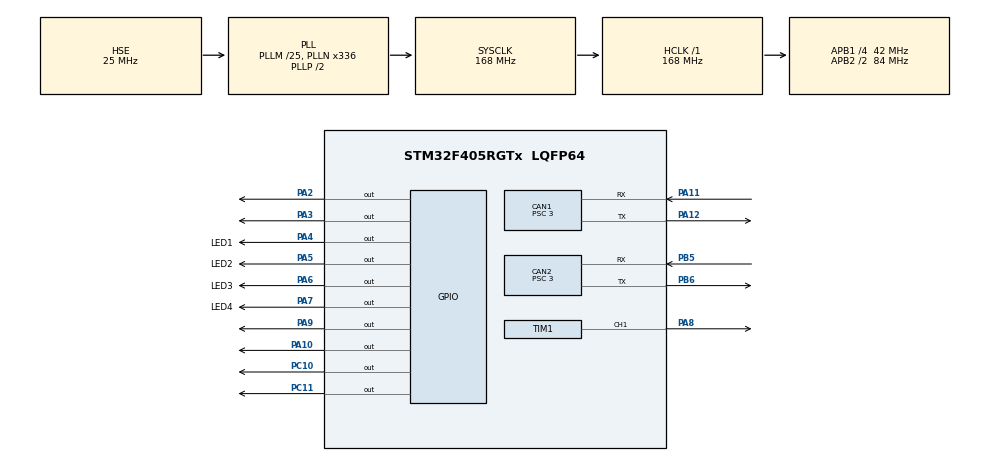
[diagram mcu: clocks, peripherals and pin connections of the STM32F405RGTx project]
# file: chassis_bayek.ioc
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CAN1.BS1=CAN_BS1_10TQ
CAN1.BS2=CAN_BS2_3TQ
CAN1.CalculateBaudRate=1000000
CAN1.CalculateTimeBit=1000
CAN1.CalculateTimeQuantum=71.42857142857143
CAN1.Prescaler=3
CAN2.BS1=CAN_BS1_10TQ
CAN2.BS2=CAN_BS2_3TQ
CAN2.CalculateBaudRate=1000000
CAN2.CalculateTimeBit=1000
CAN2.CalculateTimeQuantum=71.42857142857143
CAN2.Prescaler=3
FREERTOS.Tasks01=LEDFlow,24,128,LEDFlowFunc,As weak,NULL,Dynamic,NULL,NULL;Buzzer,24,128,buzzerFunc,As weak,NULL,Dynamic,NULL,NULL;Motor,8,128,motorFunc,As weak,NULL,Dynamic,NULL,NULL
Mcu.Family=STM32F4
Mcu.Name=STM32F405RGTx
Mcu.Package=LQFP64
NVIC.PriorityGroup=NVIC_PRIORITYGROUP_4
PA10.Signal=GPIO_Output
PA11.Mode=CAN_Activate
PA11.Signal=CAN1_RX
PA12.Mode=CAN_Activate
PA12.Signal=CAN1_TX
PA13.Mode=Serial_Wire
PA13.Signal=SYS_JTMS-SWDIO
PA14.Mode=Serial_Wire
PA14.Signal=SYS_JTCK-SWCLK
PA2.Signal=GPIO_Output
PA3.Signal=GPIO_Output
PA4.GPIO_Label=LED1
PA4.Signal=GPIO_Output
PA5.GPIO_Label=LED2
PA5.Signal=GPIO_Output
PA6.GPIO_Label=LED3
PA6.Signal=GPIO_Output
PA7.GPIO_Label=LED4
PA7.Signal=GPIO_Output
PA8.Signal=S_TIM1_CH1
PA9.Signal=GPIO_Output
PB5.Mode=CAN_Activate
PB5.Signal=CAN2_RX
PB6.Mode=CAN_Activate
PB6.Signal=CAN2_TX
PC10.Signal=GPIO_Output
PC11.Signal=GPIO_Output
PH0-OSC_IN.Mode=HSE-External-Oscillator
PH0-OSC_IN.Signal=RCC_OSC_IN
PH1-OSC_OUT.Mode=HSE-External-Oscillator
PH1-OSC_OUT.Signal=RCC_OSC_OUT
ProjectManager.HeapSize=0x200
ProjectManager.StackSize=0x400
ProjectManager.TargetToolchain=MDK-ARM V5.32
RCC.48MHZClocksFreq_Value=84000000
RCC.AHBFreq_Value=168000000
RCC.APB1CLKDivider=RCC_HCLK_DIV4
RCC.APB1Freq_Value=42000000
RCC.APB1TimFreq_Value=84000000
RCC.APB2CLKDivider=RCC_HCLK_DIV2
RCC.APB2Freq_Value=84000000
RCC.APB2TimFreq_Value=168000000
RCC.CortexFreq_Value=168000000
RCC.HCLKFreq_Value=168000000
RCC.HSE_VALUE=25000000
RCC.HSI_VALUE=16000000
RCC.LSE_VALUE=32768
RCC.PLLM=25
RCC.PLLN=336
RCC.PLLSourceVirtual=RCC_PLLSOURCE_HSE
RCC.SYSCLKFreq_VALUE=168000000
RCC.SYSCLKSource=RCC_SYSCLKSOURCE_PLLCLK
RCC.VCOOutputFreq_Value=336000000
SH.S_TIM1_CH1.0=TIM1_CH1,PWM Generation1 CH1
TIM1.Channel-PWM\ Generation1\ CH1=TIM_CHANNEL_1
TIM1.Period=840-1
TIM1.Prescaler=30-1
TIM1.Pulse-PWM\ Generation1\ CH1=100
VP_FREERTOS_VS_CMSIS_V2.Mode=CMSIS_V2
board=custom

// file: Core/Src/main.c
/* USER CODE BEGIN Header */
/**
  ******************************************************************************
  * @file           : main.c
  * @brief          : Main program body
  ******************************************************************************
  * @attention
  *
  * Copyright (c) 2025 STMicroelectronics.
  * All rights reserved.
  *
  * This software is licensed under terms that can be found in the LICENSE file
  * in the root directory of this software component.
  * If no LICENSE file comes with this software, it is provided AS-IS.
  *
  ******************************************************************************
  */
/* USER CODE END Header */
#include "main.h"
#include "cmsis_os.h"
#include "can.h"
#include "tim.h"
#include "gpio.h"

/* USER CODE BEGIN Includes */
#include "bsp_buzzer.h"
#include "EventRecorder.h"
/* USER CODE END Includes */

void SystemClock_Config(void);
void MX_FREERTOS_Init(void);

/* USER CODE BEGIN 0 */
//static int timess;
/* USER CODE END 0 */

int main(void)
{

  /* MCU Configuration--------------------------------------------------------*/

  /* Reset of all peripherals, Initializes the Flash interface and the Systick. */
  HAL_Init();

  /* Configure the system clock */
  SystemClock_Config();

  /* Initialize all configured peripherals */
  MX_GPIO_Init();
  MX_TIM1_Init();
  MX_CAN1_Init();
  MX_CAN2_Init();
  /* USER CODE BEGIN 2 */
  //start init
	// buzzer_TIM_init();
	EventRecorderInitialize(EventRecordAll, 1U);
	EventRecorderStart();

  //init success
  //buzzer play
	buzzer_play(3000, 100);
	buzzer_off();
	HAL_Delay(100);
	buzzer_play(3000, 100);

  /* USER CODE END 2 */

  /* Init scheduler */
  osKernelInitialize();

  /* Call init function for freertos objects (in cmsis_os2.c) */
  MX_FREERTOS_Init();

  /* Start scheduler */
  osKernelStart();

  /* We should never get here as control is now taken by the scheduler */

  /* Infinite loop */
  while (1)
  {

  }
}

void SystemClock_Config(void)
{
  RCC_OscInitTypeDef RCC_OscInitStruct = {0};
  RCC_ClkInitTypeDef RCC_ClkInitStruct = {0};

  /** Configure the main internal regulator output voltage
  */
  __HAL_RCC_PWR_CLK_ENABLE();
  __HAL_PWR_VOLTAGESCALING_CONFIG(PWR_REGULATOR_VOLTAGE_SCALE1);

  /** Initializes the RCC Oscillators according to the specified parameters
  * in the RCC_OscInitTypeDef structure.
  */
  RCC_OscInitStruct.OscillatorType = RCC_OSCILLATORTYPE_HSE;
  RCC_OscInitStruct.HSEState = RCC_HSE_ON;
  RCC_OscInitStruct.PLL.PLLState = RCC_PLL_ON;
  RCC_OscInitStruct.PLL.PLLSource = RCC_PLLSOURCE_HSE;
  RCC_OscInitStruct.PLL.PLLM = 25;
  RCC_OscInitStruct.PLL.PLLN = 336;
  RCC_OscInitStruct.PLL.PLLP = RCC_PLLP_DIV2;
  RCC_OscInitStruct.PLL.PLLQ = 4;
  if (HAL_RCC_OscConfig(&RCC_OscInitStruct) != HAL_OK)
  {
    Error_Handler();
  }

  /** Initializes the CPU, AHB and APB buses clocks
  */
  RCC_ClkInitStruct.ClockType = RCC_CLOCKTYPE_HCLK|RCC_CLOCKTYPE_SYSCLK
                              |RCC_CLOCKTYPE_PCLK1|RCC_CLOCKTYPE_PCLK2;
  RCC_ClkInitStruct.SYSCLKSource = RCC_SYSCLKSOURCE_PLLCLK;
  RCC_ClkInitStruct.AHBCLKDivider = RCC_SYSCLK_DIV1;
  RCC_ClkInitStruct.APB1CLKDivider = RCC_HCLK_DIV4;
  RCC_ClkInitStruct.APB2CLKDivider = RCC_HCLK_DIV2;

  if (HAL_RCC_ClockConfig(&RCC_ClkInitStruct, FLASH_LATENCY_5) != HAL_OK)
  {
    Error_Handler();
  }
}

void Error_Handler(void)
{
  __disable_irq();
  while (1)
  {
  }
}

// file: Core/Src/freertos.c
/* USER CODE BEGIN Header */
/**
  ******************************************************************************
  * File Name          : freertos.c
  * Description        : Code for freertos applications
  ******************************************************************************
  * @attention
  *
  * Copyright (c) 2025 STMicroelectronics.
  * All rights reserved.
  *
  * This software is licensed under terms that can be found in the LICENSE file
  * in the root directory of this software component.
  * If no LICENSE file comes with this software, it is provided AS-IS.
  *
  ******************************************************************************
  */
/* USER CODE END Header */

#include "FreeRTOS.h"
#include "task.h"
#include "main.h"
#include "cmsis_os.h"

/* Definitions for LEDFlow */
osThreadId_t LEDFlowHandle;
const osThreadAttr_t LEDFlow_attributes = {
  .name = "LEDFlow",
  .stack_size = 128 * 4,
  .priority = (osPriority_t) osPriorityNormal,
};
/* Definitions for Buzzer */
osThreadId_t BuzzerHandle;
const osThreadAttr_t Buzzer_attributes = {
  .name = "Buzzer",
  .stack_size = 128 * 4,
  .priority = (osPriority_t) osPriorityNormal,
};
/* Definitions for Motor */
osThreadId_t MotorHandle;
const osThreadAttr_t Motor_attributes = {
  .name = "Motor",
  .stack_size = 128 * 4,
  .priority = (osPriority_t) osPriorityLow,
};

void LEDFlowFunc(void *argument);
void buzzerFunc(void *argument);
void motorFunc(void *argument);

void MX_FREERTOS_Init(void); /* (MISRA C 2004 rule 8.1) */

void MX_FREERTOS_Init(void) {

  /* Create the thread(s) */
  /* creation of LEDFlow */
  LEDFlowHandle = osThreadNew(LEDFlowFunc, NULL, &LEDFlow_attributes);

  /* creation of Buzzer */
  BuzzerHandle = osThreadNew(buzzerFunc, NULL, &Buzzer_attributes);

  /* creation of Motor */
  MotorHandle = osThreadNew(motorFunc, NULL, &Motor_attributes);

}

__weak void LEDFlowFunc(void *argument)
{
  for(;;)
  {
    osDelay(1);
  }
}

__weak void buzzerFunc(void *argument)
{
  for(;;)
  {
    osDelay(1);
  }
}

__weak void motorFunc(void *argument)
{
  for(;;)
  {
    osDelay(1);
  }
}
